AUTOSAR XML (schema 4-3-0)
standard types defined: boolean, sint32, uint16, uint8, boolean_CompuMethod, boolean_DataConstr, sint32_DataConstr, uint16_DataConstr, uint8_DataConstr
package /ASP_DataTypes
  impl type As_BeltActivationLevel: compu {0=As_NoActivation, 1=As_ActivationLow, 2=As_ActivationHigh, 3=As_NotInUse}, implementation-data-type=sint32
  impl type As_CollisionThreatLevel: compu {0=As_Unknown, 1=As_ThreatLow, 2=As_ThreatMedium, 3=As_ThreatHigh}, implementation-data-type=sint32
  impl type As_DisplayPostEvent: compu {0=As_NoMessage, 1=As_InterventionLongitudinal, 2=As_InterventionLateral, 3=As_InterventionLongitudinalAndInterventionLateral, 4=As_BrakePulse, 5=As_CriteriaBrakeMessage}, implementation-data-type=sint32
package /ComponentTypes/FcaAdapSWC
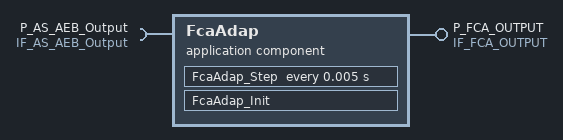
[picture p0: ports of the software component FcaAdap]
  application sw component type FcaAdap
    provide port P_FCA_OUTPUT: nonqueued-sender-com-spec{data-element=DE_FcaAdapOutput, init-value=constant-reference=CS_FCAAdap_FCA_Output}, provided-interface=IF_FCA_OUTPUT
    require port P_AS_AEB_Output: nonqueued-receiver-com-spec{data-element=DE_AS_Aeb_Output, filter=data-filter-type=ALWAYS, init-value=constant-reference=CS_FCAAdap_AebOutput}, required-interface=IF_AS_AEB_Output
    behavior FcaAdap_InternalBehavior
      init event FcaAdap_InitEvent: start-on-event=FcaAdap_Init
      timing event FcaAdap_Step_TE: start-on-event=FcaAdap_Step, period=0.005
      runnable FcaAdap_Init
        data-receive-point-by-arguments:
          access REC_P_AS_AEB_Output_DE_AS_Aeb_Output: accessed-variable=P_AS_AEB_Output.DE_AS_Aeb_Output
        data-send-points:
          access SEND_P_FCA_OUTPUT_DE_FcaAdapOutput: accessed-variable=P_FCA_OUTPUT.DE_FcaAdapOutput
      runnable FcaAdap_Step
        data-receive-point-by-arguments:
          access REC_P_AS_AEB_Output_DE_AS_Aeb_Output: accessed-variable=P_AS_AEB_Output.DE_AS_Aeb_Output
        data-send-points:
          access SEND_P_FCA_OUTPUT_DE_FcaAdapOutput: accessed-variable=P_FCA_OUTPUT.DE_FcaAdapOutput
  swc implementation FcaAdap_Implementation: behavior=FcaAdap_InternalBehavior
    code-descriptors:
      code Default: artifact-descriptors=autosar-engineering-object={short-label=Default, category=SWSRC}
package /ComponentTypes/FcaAdapSWC/Constants
  constant specification CS_FCAAdap_AebOutput: value-spec=fields=[{short-label=ForwardWarningControl, fields=[WarningRequest:0, ObjectType:0, BrakeGainEnabled:0, BrakeGainRequest:0, BrakeGainMaxDeceleration:0, TimeToCollision:0]}, {short-label=MitigationByBraking, fields=[DecelerationEnabled:0, DecelerationRequest:0, StandStillRequest:0, BeltActivationLevel:0, CollisionThreatLevel:0, DisplayPostEventMessage:0]}]
  constant specification CS_FCAAdap_FCA_Output: value-spec=fields=[FCA_WrngLvlSta:0, FCA_VehStpReq:0, FCA_StbltActvReq:0, FCA_DclReqVal:0, FCA_PrefillActvReq:0, FCA_FullActvReq:0, FCA_TimetoCllsn:0, FCA_WrngTrgtDis:0, FCA_PartialActvReq:0]
package /ComponentTypes/FcaAdapSWC/DataTypes
  5 x impl type:
    As_AebOutput: category=STRUCTURE
      element ForwardWarningControl: implementation-data-type=As_CollisionForwardWarningControl  # Examples of driver alerts are audio, visual and haptic (brake pulse) warning
      element MitigationByBraking: implementation-data-type=As_CollisionMitigationByBrakingController  # Active control of brake pressure to avoid front collision
    As_CaLongObjectType: compu {0=As_Unknown, 1=As_Car, 2=As_Motorcycle, 3=As_Truck, 4=As_Pedestrian, 5=As_Bicycle, 6=As_GeneralObject}, implementation-data-type=sint32
    As_CollisionForwardWarningControl: category=STRUCTURE
      6 x element, all with category=TYPE_REFERENCE:
        WarningRequest: implementation-data-type=boolean  # Request to activate collision warning against forward object
        ObjectType: implementation-data-type=As_CaLongObjectType  # The object type that is source of the request to activate collision warning against forward object
        BrakeGainEnabled: implementation-data-type=boolean  # Request to indicate that the current brake pressure should be amplified
        BrakeGainRequest: implementation-data-type=uint8  # Factor to increase brake pressure by
        BrakeGainMaxDeceleration: implementation-data-type=uint8  # Brake gain amplification should not cause the deceleration to be more negative than this value
        TimeToCollision: implementation-data-type=uint16  # Time to collision for primary target. Set to 100s if no value is available.
    As_CollisionMitigationByBrakingController: category=STRUCTURE
      6 x element, all with category=TYPE_REFERENCE:
        DecelerationEnabled: implementation-data-type=boolean  # Enable deceleration request
        DecelerationRequest: implementation-data-type=uint8  # Deceleration requested
        StandStillRequest: implementation-data-type=boolean  # Request to hold the vehicle stationary until driver presses the acceleration pedal
        BeltActivationLevel: implementation-data-type=As_BeltActivationLevel  # A request to activate the electric belts
        CollisionThreatLevel: implementation-data-type=As_CollisionThreatLevel  # The current collision threat level. Used by vehicle mode management to reduce electrical loads in the car and thus increase system voltage.
        DisplayPostEventMessage: implementation-data-type=As_DisplayPostEvent  # Request to driver information system to display post event message
    FCA_OUTPUTS_T: category=STRUCTURE, type-emitter=RTE
      9 x element, all with category=TYPE_REFERENCE, implementation-data-type=uint8:
        FCA_WrngLvlSta
        FCA_VehStpReq
        FCA_StbltActvReq
        FCA_DclReqVal
        FCA_PrefillActvReq
        FCA_FullActvReq
        FCA_TimetoCllsn
        FCA_WrngTrgtDis
        FCA_PartialActvReq
package /ComponentTypes/FcaAdapSWC/PortInterfaces
  sender receiver interface IF_AS_AEB_Output: invalidation-policy{data-element=DE_AS_Aeb_Output, handle-invalid=DONT-INVALIDATE}
    data DE_AS_Aeb_Output: type=As_AebOutput
  sender receiver interface IF_FCA_OUTPUT: invalidation-policy{data-element=DE_FcaAdapOutput, handle-invalid=DONT-INVALIDATE}
    data DE_FcaAdapOutput: type=FCA_OUTPUTS_T
